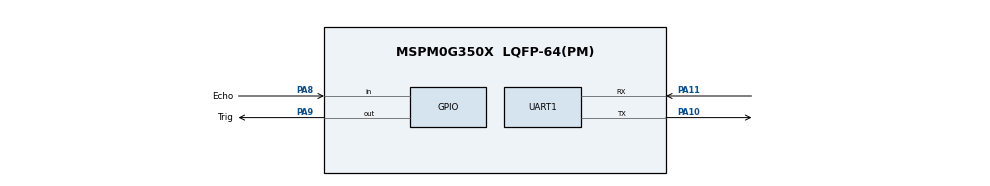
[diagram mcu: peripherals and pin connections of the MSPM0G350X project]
/**
 * @cliArgs --device "MSPM0G350X" --part "Default" --package "LQFP-64(PM)" --product "mspm0_sdk@2.10.00.04"
 * @versions {"tool":"1.27.0+4565"}
 */

/**
 * Import the modules used in this configuration.
 */
const GPIO   = scripting.addModule("/ti/driverlib/GPIO", {}, false);
const GPIO1  = GPIO.addInstance();
const SYSCTL = scripting.addModule("/ti/driverlib/SYSCTL");
const TIMER  = scripting.addModule("/ti/driverlib/TIMER", {}, false);
const TIMER1 = TIMER.addInstance();
const UART   = scripting.addModule("/ti/driverlib/UART", {}, false);
const UART1  = UART.addInstance();

/**
 * Write custom configuration values to the imported modules.
 */
GPIO1.$name                          = "SR04";
GPIO1.port                           = "PORTA";
GPIO1.associatedPins.create(2);
GPIO1.associatedPins[0].$name        = "Trig";
GPIO1.associatedPins[0].initialValue = "SET";
GPIO1.associatedPins[0].assignedPin  = "9";
GPIO1.associatedPins[0].pin.$assign  = "PA9";
GPIO1.associatedPins[1].$name        = "Echo";
GPIO1.associatedPins[1].direction    = "INPUT";
GPIO1.associatedPins[1].assignedPin  = "8";
GPIO1.associatedPins[1].interruptEn  = true;
GPIO1.associatedPins[1].polarity     = "RISE_FALL";
GPIO1.associatedPins[1].pin.$assign  = "PA8";

const Board = scripting.addModule("/ti/driverlib/Board", {}, false);

SYSCTL.forceDefaultClkConfig = true;

TIMER1.$name              = "TIMER_0";
TIMER1.timerClkPrescale   = 40;
TIMER1.timerMode          = "PERIODIC_UP";
TIMER1.timerPeriod        = "1 ms";
TIMER1.timerStartTimer    = true;
TIMER1.interrupts         = ["LOAD"];
TIMER1.interruptPriority  = "0";
TIMER1.peripheral.$assign = "TIMG0";

UART1.$name                    = "UART_0";
UART1.peripheral.$assign       = "UART0";
UART1.peripheral.rxPin.$assign = "PA11";
UART1.peripheral.txPin.$assign = "PA10";
UART1.txPinConfig.$name        = "ti_driverlib_gpio_GPIOPinGeneric0";
UART1.rxPinConfig.$name        = "ti_driverlib_gpio_GPIOPinGeneric1";

/**
 * Pinmux solution for unlocked pins/peripherals. This ensures that minor changes to the automatic solver in a future
 * version of the tool will not impact the pinmux you originally saw.  These lines can be completely deleted in order to
 * re-solve from scratch.
 */
Board.peripheral.$suggestSolution          = "DEBUGSS";
Board.peripheral.swclkPin.$suggestSolution = "PA20";
Board.peripheral.swdioPin.$suggestSolution = "PA19";
SYSCTL.peripheral.$suggestSolution         = "SYSCTL";
